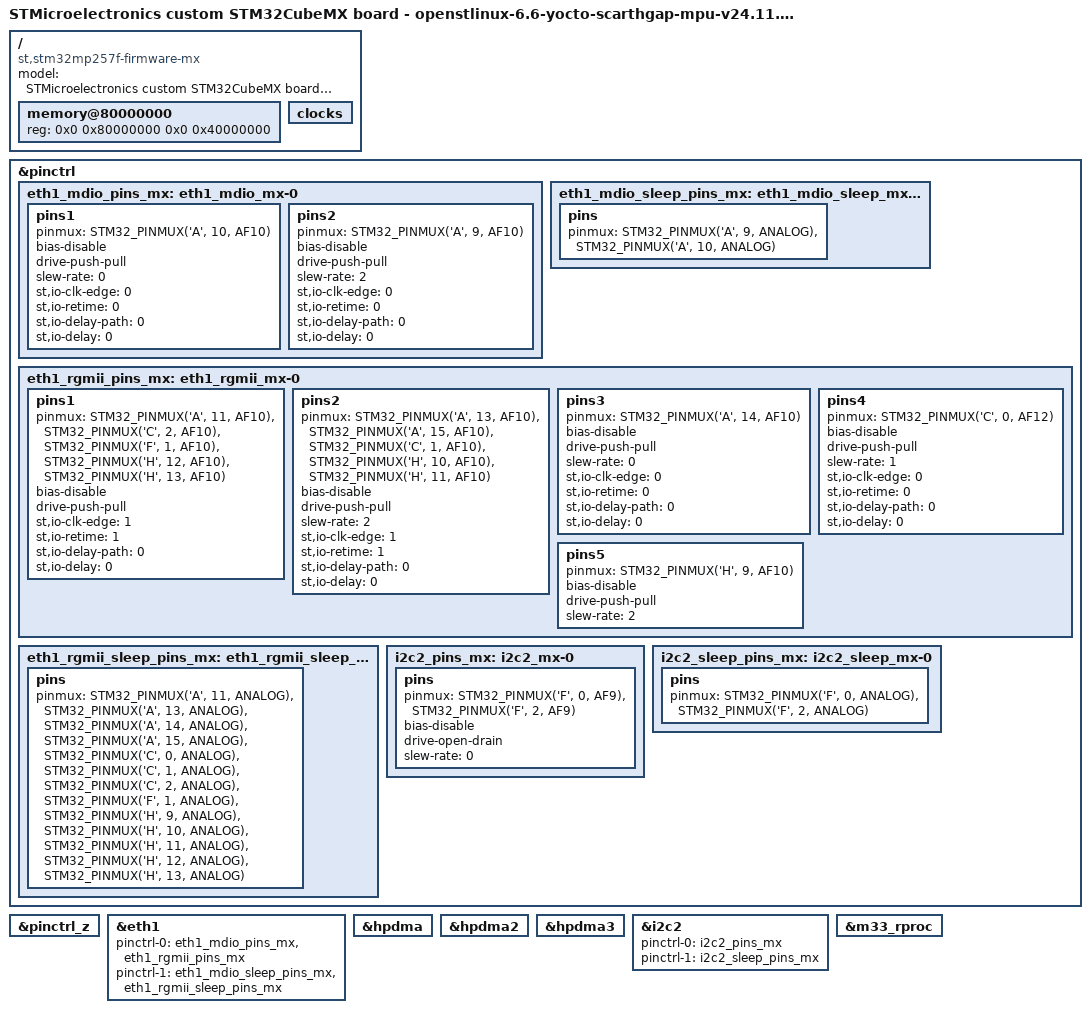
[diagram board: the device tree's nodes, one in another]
// SPDX-License-Identifier: (GPL-2.0-or-later OR BSD-3-Clause)
/*
 * Copyright (C) 2025, STMicroelectronics - All Rights Reserved
 * Author: STM32CubeMX code generation for STMicroelectronics.
 */

/* For more information on Device Tree configuration, please refer to
 * https://wiki.st.com/stm32mpu/wiki/Category:Device_tree_configuration
 */

/dts-v1/;

#include <dt-bindings/pinctrl/stm32-pinfunc.h>
#include "stm32mp257.dtsi"
#include "stm32mp25xf.dtsi"
#include "stm32mp257f-firmware-mx-resmem.dtsi"
#include "stm32mp25xxak-pinctrl.dtsi"

/* USER CODE BEGIN includes */
/* USER CODE END includes */

/ {
	model = "STMicroelectronics custom STM32CubeMX board - openstlinux-6.6-yocto-scarthgap-mpu-v24.11.06";
	compatible = "st,stm32mp257f-firmware-mx", "st,stm32mp257";

	memory@80000000 {
		device_type = "memory";
		reg = <0x0 0x80000000 0x0 0x40000000>;

		/* USER CODE BEGIN memory */
		/* USER CODE END memory */
	};

	/* USER CODE BEGIN root */
	/* USER CODE END root */

	clocks{

		/* USER CODE BEGIN clocks */
		/* USER CODE END clocks */
	};

}; /*root*/

&pinctrl {

	eth1_mdio_pins_mx: eth1_mdio_mx-0 {
		pins1 {
			pinmux = <STM32_PINMUX('A', 10, AF10)>; /* ETH1_MDIO */
			bias-disable;
			drive-push-pull;
			slew-rate = <0>;
			st,io-clk-edge = <0>;
			st,io-retime = <0>;
			st,io-delay-path = <0>;
			st,io-delay = <0>;
		};
		pins2 {
			pinmux = <STM32_PINMUX('A', 9, AF10)>; /* ETH1_MDC */
			bias-disable;
			drive-push-pull;
			slew-rate = <2>;
			st,io-clk-edge = <0>;
			st,io-retime = <0>;
			st,io-delay-path = <0>;
			st,io-delay = <0>;
		};
	};

	eth1_mdio_sleep_pins_mx: eth1_mdio_sleep_mx-0 {
		pins {
			pinmux = <STM32_PINMUX('A', 9, ANALOG)>, /* ETH1_MDC */
					 <STM32_PINMUX('A', 10, ANALOG)>; /* ETH1_MDIO */
		};
	};

	eth1_rgmii_pins_mx: eth1_rgmii_mx-0 {
		pins1 {
			pinmux = <STM32_PINMUX('A', 11, AF10)>, /* ETH1_RGMII_RX_CTL */
					 <STM32_PINMUX('C', 2, AF10)>, /* ETH1_RGMII_RXD1 */
					 <STM32_PINMUX('F', 1, AF10)>, /* ETH1_RGMII_RXD0 */
					 <STM32_PINMUX('H', 12, AF10)>, /* ETH1_RGMII_RXD2 */
					 <STM32_PINMUX('H', 13, AF10)>; /* ETH1_RGMII_RXD3 */
			bias-disable;
			drive-push-pull;
			st,io-clk-edge = <1>;
			st,io-retime = <1>;
			st,io-delay-path = <0>;
			st,io-delay = <0>;
		};
		pins2 {
			pinmux = <STM32_PINMUX('A', 13, AF10)>, /* ETH1_RGMII_TX_CTL */
					 <STM32_PINMUX('A', 15, AF10)>, /* ETH1_RGMII_TXD0 */
					 <STM32_PINMUX('C', 1, AF10)>, /* ETH1_RGMII_TXD1 */
					 <STM32_PINMUX('H', 10, AF10)>, /* ETH1_RGMII_TXD2 */
					 <STM32_PINMUX('H', 11, AF10)>; /* ETH1_RGMII_TXD3 */
			bias-disable;
			drive-push-pull;
			slew-rate = <2>;
			st,io-clk-edge = <1>;
			st,io-retime = <1>;
			st,io-delay-path = <0>;
			st,io-delay = <0>;
		};
		pins3 {
			pinmux = <STM32_PINMUX('A', 14, AF10)>; /* ETH1_RGMII_RX_CLK */
			bias-disable;
			drive-push-pull;
			slew-rate = <0>;
			st,io-clk-edge = <0>;
			st,io-retime = <0>;
			st,io-delay-path = <0>;
			st,io-delay = <0>;
		};
		pins4 {
			pinmux = <STM32_PINMUX('C', 0, AF12)>; /* ETH1_RGMII_GTX_CLK */
			bias-disable;
			drive-push-pull;
			slew-rate = <1>;
			st,io-clk-edge = <0>;
			st,io-retime = <0>;
			st,io-delay-path = <0>;
			st,io-delay = <0>;
		};
		pins5 {
			pinmux = <STM32_PINMUX('H', 9, AF10)>; /* ETH1_RGMII_CLK125 */
			bias-disable;
			drive-push-pull;
			slew-rate = <2>;
		};
	};

	eth1_rgmii_sleep_pins_mx: eth1_rgmii_sleep_mx-0 {
		pins {
			pinmux = <STM32_PINMUX('A', 11, ANALOG)>, /* ETH1_RGMII_RX_CTL */
					 <STM32_PINMUX('A', 13, ANALOG)>, /* ETH1_RGMII_TX_CTL */
					 <STM32_PINMUX('A', 14, ANALOG)>, /* ETH1_RGMII_RX_CLK */
					 <STM32_PINMUX('A', 15, ANALOG)>, /* ETH1_RGMII_TXD0 */
					 <STM32_PINMUX('C', 0, ANALOG)>, /* ETH1_RGMII_GTX_CLK */
					 <STM32_PINMUX('C', 1, ANALOG)>, /* ETH1_RGMII_TXD1 */
					 <STM32_PINMUX('C', 2, ANALOG)>, /* ETH1_RGMII_RXD1 */
					 <STM32_PINMUX('F', 1, ANALOG)>, /* ETH1_RGMII_RXD0 */
					 <STM32_PINMUX('H', 9, ANALOG)>, /* ETH1_RGMII_CLK125 */
					 <STM32_PINMUX('H', 10, ANALOG)>, /* ETH1_RGMII_TXD2 */
					 <STM32_PINMUX('H', 11, ANALOG)>, /* ETH1_RGMII_TXD3 */
					 <STM32_PINMUX('H', 12, ANALOG)>, /* ETH1_RGMII_RXD2 */
					 <STM32_PINMUX('H', 13, ANALOG)>; /* ETH1_RGMII_RXD3 */
		};
	};

	i2c2_pins_mx: i2c2_mx-0 {
		pins {
			pinmux = <STM32_PINMUX('F', 0, AF9)>, /* I2C2_SDA */
					 <STM32_PINMUX('F', 2, AF9)>; /* I2C2_SCL */
			bias-disable;
			drive-open-drain;
			slew-rate = <0>;
		};
	};

	i2c2_sleep_pins_mx: i2c2_sleep_mx-0 {
		pins {
			pinmux = <STM32_PINMUX('F', 0, ANALOG)>, /* I2C2_SDA */
					 <STM32_PINMUX('F', 2, ANALOG)>; /* I2C2_SCL */
		};
	};

	/* USER CODE BEGIN pinctrl */
	/* USER CODE END pinctrl */
};

&pinctrl_z {

	/* USER CODE BEGIN pinctrl_z */
	/* USER CODE END pinctrl_z */
};

&eth1 {
	pinctrl-names = "default", "sleep";
	pinctrl-0 = <&eth1_mdio_pins_mx>, <&eth1_rgmii_pins_mx>;
	pinctrl-1 = <&eth1_mdio_sleep_pins_mx>, <&eth1_rgmii_sleep_pins_mx>;
	status = "okay";

	/* USER CODE BEGIN eth1 */
	/* USER CODE END eth1 */
};

&hpdma {
	status = "okay";

	/* USER CODE BEGIN hpdma */
	/* USER CODE END hpdma */
};

&hpdma2 {
	status = "okay";

	/* USER CODE BEGIN hpdma2 */
	/* USER CODE END hpdma2 */
};

&hpdma3 {
	status = "okay";

	/* USER CODE BEGIN hpdma3 */
	/* USER CODE END hpdma3 */
};

&i2c2 {
	pinctrl-names = "default", "sleep";
	pinctrl-0 = <&i2c2_pins_mx>;
	pinctrl-1 = <&i2c2_sleep_pins_mx>;
	status = "okay";

	/* USER CODE BEGIN i2c2 */
	/* USER CODE END i2c2 */
};

&m33_rproc {
	status = "okay";

	/* USER CODE BEGIN m33_rproc */
	/* USER CODE END m33_rproc */
};

/* USER CODE BEGIN addons */
/* USER CODE END addons */

